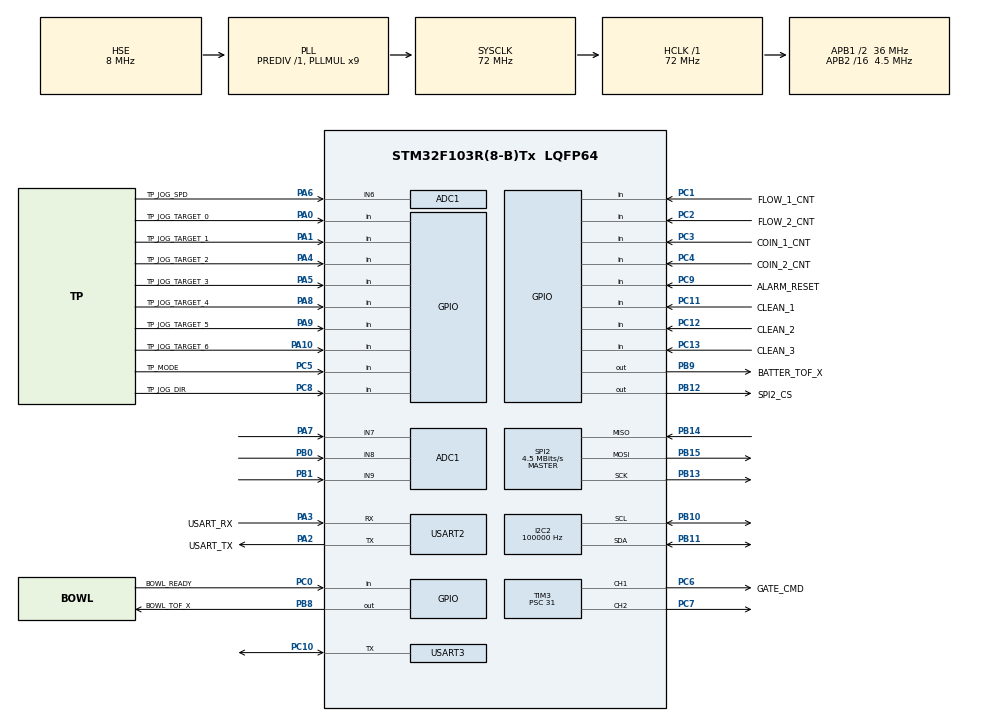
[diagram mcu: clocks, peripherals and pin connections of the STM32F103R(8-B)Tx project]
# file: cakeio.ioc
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ADC1.Channel-2\#ChannelRegularConversion=ADC_CHANNEL_6
ADC1.Channel-3\#ChannelRegularConversion=ADC_CHANNEL_6
ADC1.Channel-4\#ChannelRegularConversion=ADC_CHANNEL_6
ADC1.Channel-5\#ChannelRegularConversion=ADC_CHANNEL_6
ADC1.ContinuousConvMode=ENABLE
ADC1.NbrOfConversion=4
ADC1.NbrOfConversionFlag=1
ADC1.Rank-2\#ChannelRegularConversion=1
ADC1.Rank-3\#ChannelRegularConversion=2
ADC1.Rank-4\#ChannelRegularConversion=3
ADC1.Rank-5\#ChannelRegularConversion=4
ADC1.SamplingTime-2\#ChannelRegularConversion=ADC_SAMPLETIME_1CYCLE_5
ADC1.SamplingTime-3\#ChannelRegularConversion=ADC_SAMPLETIME_1CYCLE_5
ADC1.SamplingTime-4\#ChannelRegularConversion=ADC_SAMPLETIME_1CYCLE_5
ADC1.SamplingTime-5\#ChannelRegularConversion=ADC_SAMPLETIME_1CYCLE_5
ADC1.master=1
Dma.ADC1.5.Direction=DMA_PERIPH_TO_MEMORY
Dma.ADC1.5.Instance=DMA1_Channel1
Dma.ADC1.5.MemDataAlignment=DMA_MDATAALIGN_HALFWORD
Dma.ADC1.5.MemInc=DMA_MINC_ENABLE
Dma.ADC1.5.Mode=DMA_CIRCULAR
Dma.ADC1.5.PeriphDataAlignment=DMA_PDATAALIGN_HALFWORD
Dma.ADC1.5.PeriphInc=DMA_PINC_DISABLE
Dma.ADC1.5.Priority=DMA_PRIORITY_LOW
Dma.I2C2_RX.3.Direction=DMA_PERIPH_TO_MEMORY
Dma.I2C2_RX.3.Instance=DMA1_Channel5
Dma.I2C2_RX.3.MemDataAlignment=DMA_MDATAALIGN_BYTE
Dma.I2C2_RX.3.MemInc=DMA_MINC_ENABLE
Dma.I2C2_RX.3.Mode=DMA_NORMAL
Dma.I2C2_RX.3.PeriphDataAlignment=DMA_PDATAALIGN_BYTE
Dma.I2C2_RX.3.PeriphInc=DMA_PINC_DISABLE
Dma.I2C2_RX.3.Priority=DMA_PRIORITY_LOW
Dma.I2C2_TX.2.Direction=DMA_MEMORY_TO_PERIPH
Dma.I2C2_TX.2.Instance=DMA1_Channel4
Dma.I2C2_TX.2.MemDataAlignment=DMA_MDATAALIGN_BYTE
Dma.I2C2_TX.2.MemInc=DMA_MINC_ENABLE
Dma.I2C2_TX.2.Mode=DMA_NORMAL
Dma.I2C2_TX.2.PeriphDataAlignment=DMA_PDATAALIGN_BYTE
Dma.I2C2_TX.2.PeriphInc=DMA_PINC_DISABLE
Dma.I2C2_TX.2.Priority=DMA_PRIORITY_LOW
Dma.Request0=USART3_TX
Dma.Request1=USART3_RX
Dma.Request2=I2C2_TX
Dma.Request3=I2C2_RX
Dma.Request4=USART2_RX
Dma.Request5=ADC1
Dma.USART2_RX.4.Direction=DMA_PERIPH_TO_MEMORY
Dma.USART2_RX.4.Instance=DMA1_Channel6
Dma.USART2_RX.4.MemDataAlignment=DMA_MDATAALIGN_BYTE
Dma.USART2_RX.4.MemInc=DMA_MINC_ENABLE
Dma.USART2_RX.4.Mode=DMA_CIRCULAR
Dma.USART2_RX.4.PeriphDataAlignment=DMA_PDATAALIGN_BYTE
Dma.USART2_RX.4.PeriphInc=DMA_PINC_DISABLE
Dma.USART2_RX.4.Priority=DMA_PRIORITY_LOW
Dma.USART3_RX.1.Direction=DMA_PERIPH_TO_MEMORY
Dma.USART3_RX.1.Instance=DMA1_Channel3
Dma.USART3_RX.1.MemDataAlignment=DMA_MDATAALIGN_BYTE
Dma.USART3_RX.1.MemInc=DMA_MINC_ENABLE
Dma.USART3_RX.1.Mode=DMA_NORMAL
Dma.USART3_RX.1.PeriphDataAlignment=DMA_PDATAALIGN_BYTE
Dma.USART3_RX.1.PeriphInc=DMA_PINC_DISABLE
Dma.USART3_RX.1.Priority=DMA_PRIORITY_LOW
Dma.USART3_TX.0.Direction=DMA_MEMORY_TO_PERIPH
Dma.USART3_TX.0.Instance=DMA1_Channel2
Dma.USART3_TX.0.MemDataAlignment=DMA_MDATAALIGN_BYTE
Dma.USART3_TX.0.MemInc=DMA_MINC_ENABLE
Dma.USART3_TX.0.Mode=DMA_NORMAL
Dma.USART3_TX.0.PeriphDataAlignment=DMA_PDATAALIGN_BYTE
Dma.USART3_TX.0.PeriphInc=DMA_PINC_DISABLE
Dma.USART3_TX.0.Priority=DMA_PRIORITY_LOW
I2C2.ClockSpeed=100000
Mcu.Family=STM32F1
Mcu.Name=STM32F103R(8-B)Tx
Mcu.Package=LQFP64
NVIC.DMA1_Channel1_IRQn=true\:0\:0\:false\:false\:true\:false\:true
NVIC.DMA1_Channel2_IRQn=true\:0\:0\:false\:false\:true\:false\:true
NVIC.DMA1_Channel3_IRQn=true\:0\:0\:false\:false\:true\:false\:true
NVIC.DMA1_Channel4_IRQn=true\:0\:0\:false\:false\:true\:false\:true
NVIC.DMA1_Channel5_IRQn=true\:0\:0\:false\:false\:true\:false\:true
NVIC.DMA1_Channel6_IRQn=true\:0\:0\:false\:false\:true\:false\:true
NVIC.I2C2_ER_IRQn=true\:0\:0\:false\:false\:true\:true\:true
NVIC.I2C2_EV_IRQn=true\:0\:0\:false\:false\:true\:true\:true
NVIC.PriorityGroup=NVIC_PRIORITYGROUP_4
NVIC.SPI2_IRQn=true\:0\:0\:false\:false\:true\:true\:true
NVIC.TIM1_UP_IRQn=true\:0\:0\:false\:false\:true\:false\:true
NVIC.TIM3_IRQn=true\:0\:0\:false\:false\:true\:true\:true
NVIC.TimeBase=TIM1_UP_IRQn
NVIC.TimeBaseIP=TIM1
NVIC.USART2_IRQn=true\:0\:0\:false\:false\:true\:true\:true
NVIC.USART3_IRQn=true\:5\:0\:true\:false\:true\:true\:true
PA0-WKUP.GPIO_Label=TP_JOG_TARGET_0
PA0-WKUP.Signal=GPIO_Input
PA1.GPIO_Label=TP_JOG_TARGET_1
PA1.Signal=GPIO_Input
PA10.GPIO_Label=TP_JOG_TARGET_6
PA10.Signal=GPIO_Input
PA13.GPIO_Label=TMS
PA13.Mode=Serial_Wire
PA13.Signal=SYS_JTMS-SWDIO
PA14.GPIO_Label=TCK
PA14.Mode=Serial_Wire
PA14.Signal=SYS_JTCK-SWCLK
PA2.GPIO_Label=USART_TX
PA2.GPIO_Mode=GPIO_MODE_AF_PP
PA2.GPIO_PuPd=GPIO_NOPULL
PA2.GPIO_Speed=GPIO_SPEED_FREQ_LOW
PA2.Mode=Asynchronous
PA2.Signal=USART2_TX
PA3.GPIO_Label=USART_RX
PA3.GPIO_Mode=GPIO_MODE_AF_PP
PA3.GPIO_PuPd=GPIO_NOPULL
PA3.GPIO_Speed=GPIO_SPEED_FREQ_LOW
PA3.Mode=Asynchronous
PA3.Signal=USART2_RX
PA4.GPIO_Label=TP_JOG_TARGET_2
PA4.Signal=GPIO_Input
PA5.GPIO_Label=TP_JOG_TARGET_3
PA5.Signal=GPIO_Input
PA6.GPIO_Label=TP_JOG_SPD
PA6.Signal=ADCx_IN6
PA7.Signal=ADCx_IN7
PA8.GPIO_Label=TP_JOG_TARGET_4
PA8.Signal=GPIO_Input
PA9.GPIO_Label=TP_JOG_TARGET_5
PA9.Signal=GPIO_Input
PB0.Signal=ADCx_IN8
PB1.Signal=ADCx_IN9
PB10.Mode=I2C
PB10.Signal=I2C2_SCL
PB11.Mode=I2C
PB11.Signal=I2C2_SDA
PB12.GPIO_Label=SPI2_CS
PB12.Signal=GPIO_Output
PB13.Mode=Full_Duplex_Master
PB13.Signal=SPI2_SCK
PB14.Mode=Full_Duplex_Master
PB14.Signal=SPI2_MISO
PB15.Mode=Full_Duplex_Master
PB15.Signal=SPI2_MOSI
PB3.GPIO_Label=SWO
PB3.Signal=SYS_JTDO-TRACESWO
PB8.GPIO_Label=BOWL_TOF_X
PB8.PinState=GPIO_PIN_SET
PB8.Signal=GPIO_Output
PB9.GPIO_Label=BATTER_TOF_X
PB9.PinState=GPIO_PIN_SET
PB9.Signal=GPIO_Output
PC0.GPIO_Label=BOWL_READY
PC0.Signal=GPIO_Input
PC1.GPIO_Label=FLOW_1_CNT
PC1.Signal=GPIO_Input
PC10.Mode=Half_duplex(single_wire_mode)
PC10.Signal=USART3_TX
PC11.GPIO_Label=CLEAN_1
PC11.Signal=GPIO_Input
PC12.GPIO_Label=CLEAN_2
PC12.Signal=GPIO_Input
PC13-TAMPER-RTC.GPIO_Label=CLEAN_3
PC13-TAMPER-RTC.Signal=GPIO_Input
PC14-OSC32_IN.Mode=LSE-External-Oscillator
PC14-OSC32_IN.Signal=RCC_OSC32_IN
PC15-OSC32_OUT.Mode=LSE-External-Oscillator
PC15-OSC32_OUT.Signal=RCC_OSC32_OUT
PC2.GPIO_Label=FLOW_2_CNT
PC2.Signal=GPIO_Input
PC3.GPIO_Label=COIN_1_CNT
PC3.Signal=GPIO_Input
PC4.GPIO_Label=COIN_2_CNT
PC4.Signal=GPIO_Input
PC5.GPIO_Label=TP_MODE
PC5.Signal=GPIO_Input
PC6.GPIO_Label=GATE_CMD
PC6.Signal=S_TIM3_CH1
PC7.Signal=S_TIM3_CH2
PC8.GPIO_Label=TP_JOG_DIR
PC8.Signal=GPIO_Input
PC9.GPIO_Label=ALARM_RESET
PC9.Signal=GPIO_Input
PD0-OSC_IN.Mode=HSE-External-Clock-Source
PD0-OSC_IN.Signal=RCC_OSC_IN
PD1-OSC_OUT.Mode=HSE-External-Clock-Source
PD1-OSC_OUT.Signal=RCC_OSC_OUT
ProjectManager.HeapSize=0x200
ProjectManager.StackSize=0x400
ProjectManager.TargetToolchain=STM32CubeIDE
RCC.ADCPresc=RCC_ADCPCLK2_DIV8
RCC.AHBFreq_Value=72000000
RCC.APB1CLKDivider=RCC_HCLK_DIV2
RCC.APB1Freq_Value=36000000
RCC.APB1TimFreq_Value=72000000
RCC.APB2CLKDivider=RCC_HCLK_DIV16
RCC.APB2Freq_Value=4500000
RCC.APB2TimFreq_Value=9000000
RCC.HCLKFreq_Value=72000000
RCC.PLLMUL=RCC_PLL_MUL9
RCC.PLLSourceVirtual=RCC_PLLSOURCE_HSE
RCC.RTCClockSelection=RCC_RTCCLKSOURCE_LSE
RCC.SYSCLKFreq_VALUE=72000000
RCC.SYSCLKSource=RCC_SYSCLKSOURCE_PLLCLK
RCC.USBFreq_Value=72000000
SH.ADCx_IN6.0=ADC1_IN6,IN6
SH.ADCx_IN7.0=ADC1_IN7,IN7
SH.ADCx_IN8.0=ADC1_IN8,IN8
SH.ADCx_IN9.0=ADC1_IN9,IN9
SH.S_TIM3_CH1.0=TIM3_CH1,PWM Generation1 CH1
SH.S_TIM3_CH2.0=TIM3_CH2,PWM Generation2 CH2
SPI2.BaudRatePrescaler=SPI_BAUDRATEPRESCALER_8
SPI2.CalculateBaudRate=4.5 MBits/s
SPI2.Direction=SPI_DIRECTION_2LINES
SPI2.Mode=SPI_MODE_MASTER
SPI2.VirtualType=VM_MASTER
TIM3.AutoReloadPreload=TIM_AUTORELOAD_PRELOAD_ENABLE
TIM3.Channel-PWM\ Generation1\ CH1=TIM_CHANNEL_1
TIM3.Channel-PWM\ Generation2\ CH2=TIM_CHANNEL_2
TIM3.OCPolarity_1=TIM_OCPOLARITY_LOW
TIM3.OCPolarity_2=TIM_OCPOLARITY_LOW
TIM3.Period=499
TIM3.Prescaler=31
TIM3.Pulse-PWM\ Generation1\ CH1=0
TIM3.Pulse-PWM\ Generation2\ CH2=0
USART2.VirtualMode=VM_ASYNC
USART3.VirtualMode=VM_ASYNC
VP_CRC_VS_CRC.Mode=CRC_Activate
VP_SYS_VS_tim1.Mode=TIM1
VP_TIM3_VS_ClockSourceINT.Mode=Internal
board=NUCLEO-F103RB

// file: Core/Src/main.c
/* USER CODE BEGIN Header */
/**
  ******************************************************************************
  * @file           : main.c
  * @brief          : Main program body
  ******************************************************************************
  * @attention
  *
  * <h2><center>&copy; Copyright (c) 2021 STMicroelectronics.
  * All rights reserved.</center></h2>
  *
  * This software component is licensed by ST under BSD 3-Clause license,
  * the "License"; You may not use this file except in compliance with the
  * License. You may obtain a copy of the License at:
  *                        opensource.org/licenses/BSD-3-Clause
  *
  ******************************************************************************
  */
/* USER CODE END Header */
#include "main.h"
#include "adc.h"
#include "crc.h"
#include "dma.h"
#include "i2c.h"
#include "spi.h"
#include "tim.h"
#include "usart.h"
#include "gpio.h"

/* USER CODE BEGIN Includes */
#include "cake_io.h"
/* USER CODE END Includes */

void SystemClock_Config(void);

int main(void)
{

  /* MCU Configuration--------------------------------------------------------*/

  /* Reset of all peripherals, Initializes the Flash interface and the Systick. */
  HAL_Init();

  /* Configure the system clock */
  SystemClock_Config();

  /* Initialize all configured peripherals */
  MX_GPIO_Init();
  MX_DMA_Init();
  MX_USART2_UART_Init();
  MX_USART3_UART_Init();
  MX_I2C2_Init();
  MX_SPI2_Init();
  MX_ADC1_Init();
  MX_CRC_Init();
  MX_TIM3_Init();
  /* USER CODE BEGIN 2 */
  cake_io_init();
  /* USER CODE END 2 */

  /* Infinite loop */
  while (1)
  {
	  cake_io_cyclic();
  }
}

void SystemClock_Config(void)
{
  RCC_OscInitTypeDef RCC_OscInitStruct = {0};
  RCC_ClkInitTypeDef RCC_ClkInitStruct = {0};
  RCC_PeriphCLKInitTypeDef PeriphClkInit = {0};

  /** Initializes the RCC Oscillators according to the specified parameters
  * in the RCC_OscInitTypeDef structure.
  */
  RCC_OscInitStruct.OscillatorType = RCC_OSCILLATORTYPE_HSE;
  RCC_OscInitStruct.HSEState = RCC_HSE_BYPASS;
  RCC_OscInitStruct.HSEPredivValue = RCC_HSE_PREDIV_DIV1;
  RCC_OscInitStruct.HSIState = RCC_HSI_ON;
  RCC_OscInitStruct.PLL.PLLState = RCC_PLL_ON;
  RCC_OscInitStruct.PLL.PLLSource = RCC_PLLSOURCE_HSE;
  RCC_OscInitStruct.PLL.PLLMUL = RCC_PLL_MUL9;
  if (HAL_RCC_OscConfig(&RCC_OscInitStruct) != HAL_OK)
  {
    Error_Handler();
  }
  /** Initializes the CPU, AHB and APB buses clocks
  */
  RCC_ClkInitStruct.ClockType = RCC_CLOCKTYPE_HCLK|RCC_CLOCKTYPE_SYSCLK
                              |RCC_CLOCKTYPE_PCLK1|RCC_CLOCKTYPE_PCLK2;
  RCC_ClkInitStruct.SYSCLKSource = RCC_SYSCLKSOURCE_PLLCLK;
  RCC_ClkInitStruct.AHBCLKDivider = RCC_SYSCLK_DIV1;
  RCC_ClkInitStruct.APB1CLKDivider = RCC_HCLK_DIV2;
  RCC_ClkInitStruct.APB2CLKDivider = RCC_HCLK_DIV16;

  if (HAL_RCC_ClockConfig(&RCC_ClkInitStruct, FLASH_LATENCY_2) != HAL_OK)
  {
    Error_Handler();
  }
  PeriphClkInit.PeriphClockSelection = RCC_PERIPHCLK_ADC;
  PeriphClkInit.AdcClockSelection = RCC_ADCPCLK2_DIV8;
  if (HAL_RCCEx_PeriphCLKConfig(&PeriphClkInit) != HAL_OK)
  {
    Error_Handler();
  }
}

 /**
  * @brief  Period elapsed callback in non blocking mode
  * @note   This function is called  when TIM1 interrupt took place, inside
  * HAL_TIM_IRQHandler(). It makes a direct call to HAL_IncTick() to increment
  * a global variable "uwTick" used as application time base.
  * @param  htim : TIM handle
  * @retval None
  */
void HAL_TIM_PeriodElapsedCallback(TIM_HandleTypeDef *htim)
{
  if (htim->Instance == TIM1) {
    HAL_IncTick();
  }
}

void Error_Handler(void)
{
  __disable_irq();
  while (1)
  {
  }
}

/************************ (C) COPYRIGHT STMicroelectronics *****END OF FILE****/
